# MB9AF34xN register map
File version: 1.7
Registers are 32-bit, read-write, reset 0x0 unless marked. A register's access mark holds for its fields unless they carry their own. Offsets are from the block's base; [hi:lo] are bit positions; {n}, {i} and the like mark numbered series.

## INTREQ — Interrupts
Base 0x40031000
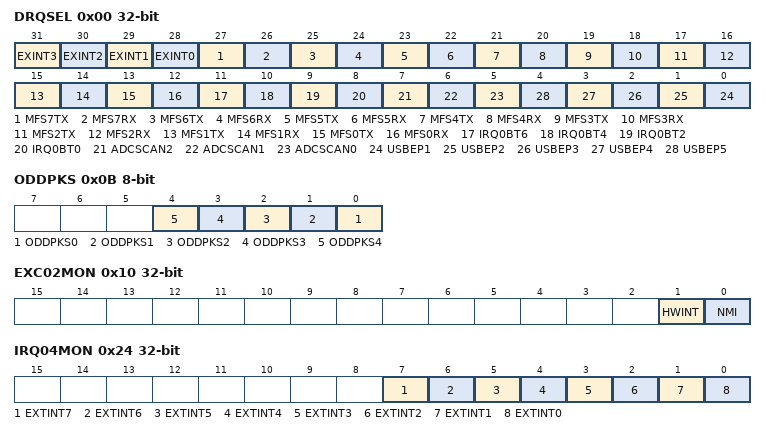
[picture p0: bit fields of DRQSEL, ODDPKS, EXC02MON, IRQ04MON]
0x00 DRQSEL — DMA Request Selection Register
  [31] EXINT3 — The interrupt signal of the external interrupt ch.3 is output as a transfer request to the DMAC (including extension).
  [30] EXINT2 — The interrupt signal of the external interrupt ch.2 is output as a transfer request to the DMAC (including extension).
  [29] EXINT1 — The interrupt signal of the external interrupt ch.1 is output as a transfer request to the DMAC (including extension).
  [28] EXINT0 — The interrupt signal of the external interrupt ch.0 is output as a transfer request to the DMAC (including extension).
  [27] MFS7TX — The transmission interrupt signal of the MFS ch.7 is output as a transfer request to the DMAC (including extension).
  [26] MFS7RX — The reception interrupt signal of the MFS ch.7 is output as a transfer request to the DMAC (including extension).
  [25] MFS6TX — The transmission interrupt signal of the MFS ch.6 is output as a transfer request to the DMAC (including extension).
  [24] MFS6RX — The reception interrupt signal of the MFS ch.6 is output as a transfer request to the DMAC (including extension).
  [23] MFS5TX — The transmission interrupt signal of the MFS ch.5 is output as a transfer request to the DMAC (including extension).
  [22] MFS5RX — The reception interrupt signal of the MFS ch.5 is output as a transfer request to the DMAC (including extension).
  [21] MFS4TX — The transmission interrupt signal of the MFS ch.4 is output as a transfer request to the DMAC (including extension).
  [20] MFS4RX — The reception interrupt signal of the MFS ch.4 is output as a transfer request to the DMAC (including extension).
  [19] MFS3TX — The transmission interrupt signal of the MFS ch.3 is output as a transfer request to the DMAC (including extension).
  [18] MFS3RX — The reception interrupt signal of the MFS ch.3 is output as a transfer request to the DMAC (including extension).
  [17] MFS2TX — The transmission interrupt signal of the MFS ch.2 is output as a transfer request to the DMAC (including extension).
  [16] MFS2RX — The reception interrupt signal of the MFS ch.2 is output as a transfer request to the DMAC (including extension).
  [15] MFS1TX — The transmission interrupt signal of the MFS ch.1 is output as a transfer request to the DMAC (including extension).
  [14] MFS1RX — The reception interrupt signal of the MFS ch.1 is output as a transfer request to the DMAC (including extension).
  [13] MFS0TX — The transmission interrupt signal of the MFS ch.0 is output as a transfer request to the DMAC (including extension).
  [12] MFS0RX — The reception interrupt signal of the MFS ch.0 is output as a transfer request to the DMAC (including extension).
  [11] IRQ0BT6 — The IRQ0 interrupt signal of the base timer ch.6 is output as a transfer request to the DMAC.
  [10] IRQ0BT4 — The IRQ0 interrupt signal of the base timer ch.4 is output as a transfer request to the DMAC.
  [9] IRQ0BT2 — The IRQ0 interrupt signal of the base timer ch.3 is output as a transfer request to the DMAC.
  [8] IRQ0BT0 — The IRQ0 interrupt signal of the base timer ch.0 is output as a transfer request to the DMAC.
  [7] ADCSCAN2 — The scan conversion interrupt signal of the A/D converter unit 2 is output as a transfer request to the DMAC.
  [6] ADCSCAN1 — The scan conversion interrupt signal of the A/D converter unit 1 is output as a transfer request to the DMAC.
  [5] ADCSCAN0 — The scan conversion interrupt signal of the A/D converter unit 0 is output as a transfer request to the DMAC.
  [n-1] USBEP{n} (n=1..5) — The EP{n} DRQ interrupt signal of the USB ch.0 is output as a transfer request to the DMAC.
0x0B ODDPKS 8-bit — USB ch.0 Odd Packet Size DMA Enable Register
  [n] ODDPKS{n} (n=0..4) — "When the transfer destination address of DMAC is USB.EP{n+1}DT, the bit width of the last transfer data is converted to Byte."
0x0C IRQCMODE — Interrupt Factor Vector Relocate Setting Register
  [0] IRQCMODE — Interrupt Factor Vector Relocate Setting
0x10 EXC02MON ro — EXC02 batch read register
  [1] HWINT — Hardware watchdog timer interrupt request
  [0] NMI — External NMIX pin interrupt request
0x14 IRQ00MON ro — IRQ00 Batch Read Register
  [0] FCSINT — Anomalous frequency detection by CSV interrupt request
0x18 IRQ01MON ro — IRQ01 Batch Read Register
  [0] SWWDTINT — Software watchdog timer interrupt request
0x1C IRQ02MON ro — IRQ02 Batch Read Register
  [0] LVDINT — Low voltage detection (LVD) interrupt request
0x24 IRQ04MON ro — IRQ04 Batch Read Register
  [7] EXTINT7 — Interrupt request on external interrupt ch.7
  [6] EXTINT6 — Interrupt request on external interrupt ch.6
  [5] EXTINT5 — Interrupt request on external interrupt ch.5
  [4] EXTINT4 — Interrupt request on external interrupt ch.4
  [3] EXTINT3 — Interrupt request on external interrupt ch.3
  [2] EXTINT2 — Interrupt request on external interrupt ch.2
  [1] EXTINT1 — Interrupt request on external interrupt ch.1
  [0] EXTINT0 — Interrupt request on external interrupt ch.0
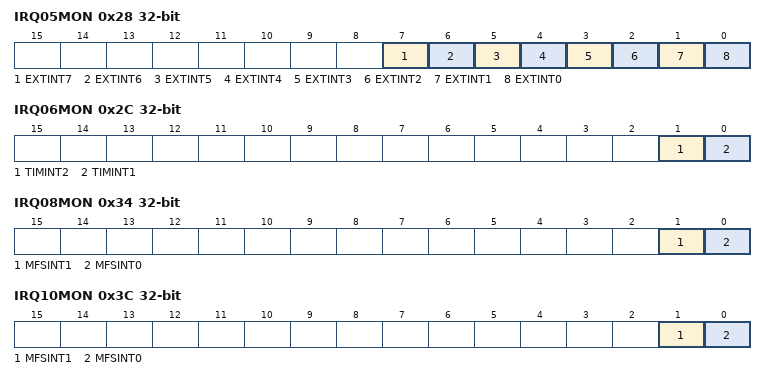
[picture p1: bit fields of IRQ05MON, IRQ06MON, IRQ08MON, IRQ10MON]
0x28 IRQ05MON ro — IRQ05 Batch Read Register
  [7] EXTINT7 — Interrupt request on external interrupt ch.15
  [6] EXTINT6 — Interrupt request on external interrupt ch.14
  [5] EXTINT5 — Interrupt request on external interrupt ch.13
  [4] EXTINT4 — Interrupt request on external interrupt ch.12
  [3] EXTINT3 — Interrupt request on external interrupt ch.11
  [2] EXTINT2 — Interrupt request on external interrupt ch.10
  [1] EXTINT1 — Interrupt request on external interrupt ch.9
  [0] EXTINT0 — Interrupt request on external interrupt ch.8
0x2C IRQ06MON ro — IRQ06 Batch Read Register
  [1] TIMINT2 — Dual timer 2 interrupt request
  [0] TIMINT1 — Dual timer 1 interrupt request
0x30 IRQ07MON ro — IRQ07 Batch Read Register
  [0] MFSINT — Reception interrupt request on MFS ch.0
0x34 IRQ08MON ro — IRQ08 Batch Read Register
  [1] MFSINT1 — Status interrupt request on MFS ch.0
  [0] MFSINT0 — Transmission interrupt request on MFS ch.0
0x38 IRQ09MON ro — IRQ09 Batch Read Register
  [0] MFSINT — Reception interrupt request on MFS ch.1
0x3C IRQ10MON ro — IRQ10 Batch Read Register
  [1] MFSINT1 — Status interrupt request on MFS ch.1
  [0] MFSINT0 — Transmission interrupt request on MFS ch.1
0x40 IRQ11MON ro — IRQ11 Batch Read Register
  [0] MFSINT — Reception interrupt request on MFS ch.2
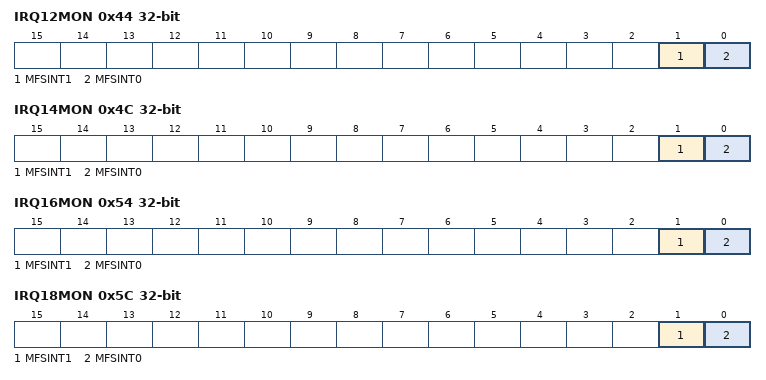
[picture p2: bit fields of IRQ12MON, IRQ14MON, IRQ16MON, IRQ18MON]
0x44 IRQ12MON ro — IRQ12 Batch Read Register
  [1] MFSINT1 — Status interrupt request on MFS ch.2
  [0] MFSINT0 — Transmission interrupt request on MFS ch.2
0x48 IRQ13MON ro — IRQ13 Batch Read Register
  [0] MFSINT — Reception interrupt request on MFS ch.3
0x4C IRQ14MON ro — IRQ14 Batch Read Register
  [1] MFSINT1 — Status interrupt request on MFS ch.3
  [0] MFSINT0 — Transmission interrupt request on MFS ch.3
0x50 IRQ15MON ro — IRQ15 Batch Read Register
  [0] MFSINT — Reception interrupt request on MFS ch.4
0x54 IRQ16MON ro — IRQ16 Batch Read Register
  [1] MFSINT1 — Status interrupt request on MFS ch.4
  [0] MFSINT0 — Transmission interrupt request on MFS ch.4
0x58 IRQ17MON ro — IRQ17 Batch Read Register
  [0] MFSINT — Reception interrupt request on MFS ch.5
0x5C IRQ18MON ro — IRQ18 Batch Read Register
  [1] MFSINT1 — Status interrupt request on MFS ch.5
  [0] MFSINT0 — Transmission interrupt request on MFS ch.5
0x60 IRQ19MON ro — IRQ19 Batch Read Register
  [0] MFSINT — Reception interrupt request on MFS ch.6
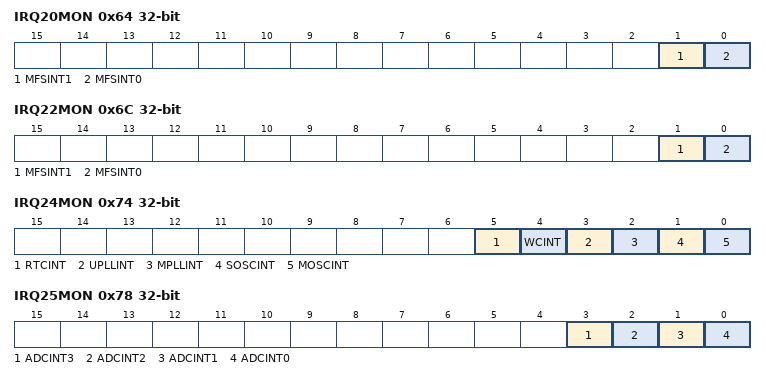
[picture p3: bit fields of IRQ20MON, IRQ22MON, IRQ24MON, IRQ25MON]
0x64 IRQ20MON ro — IRQ20 Batch Read Register
  [1] MFSINT1 — Status interrupt request on MFS ch.6
  [0] MFSINT0 — Transmission interrupt request on MFS ch.6
0x68 IRQ21MON ro — IRQ21 Batch Read Register
  [0] MFSINT — Reception interrupt request on MFS ch.7
0x6C IRQ22MON ro — IRQ22 Batch Read Register
  [1] MFSINT1 — Status interrupt request on MFS ch.7
  [0] MFSINT0 — Transmission interrupt request on MFS ch.7
0x74 IRQ24MON ro — IRQ24 Batch Read Register
  [5] RTCINT — RTC interrupt request
  [4] WCINT — Watch counter interrupt request
  [3] UPLLINT — Stabilization wait completion interrupt request for USB or USB/Ethernet PLL oscillation.
  [2] MPLLINT — Stabilization wait completion interrupt request for main PLL oscillation
  [1] SOSCINT — Stabilization wait completion interrupt request for sub-clock oscillation
  [0] MOSCINT — Stabilization wait completion interrupt request for main clock oscillation
0x78 IRQ25MON ro — IRQ25 Batch Read Register
  [3] ADCINT3 — Conversion result comparison interrupt request in the corresponding A/D unit 0.
  [2] ADCINT2 — FIFO overrun interrupt request in the corresponding A/D unit 0.
  [1] ADCINT1 — Scan conversion interrupt request in the corresponding A/D unit 0.
  [0] ADCINT0 — Priority conversion interrupt request in the corresponding A/D unit 0.
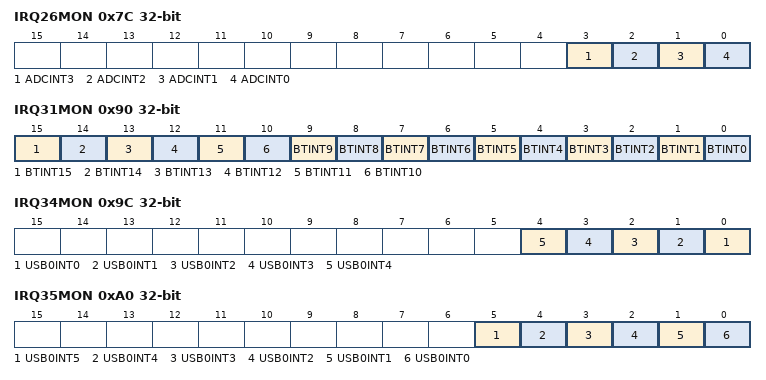
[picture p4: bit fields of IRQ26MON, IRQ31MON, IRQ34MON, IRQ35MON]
0x7C IRQ26MON ro — IRQ26 Batch Read Register
  [3] ADCINT3 — Conversion result comparison interrupt request in the corresponding A/D unit 1
  [2] ADCINT2 — FIFO overrun interrupt request in the corresponding A/D unit 1
  [1] ADCINT1 — Scan conversion interrupt request in the corresponding A/D unit 1
  [0] ADCINT0 — Priority conversion interrupt request in the corresponding A/D unit 1
0x90 IRQ31MON ro — IRQ31 Batch Read Register
  [15] BTINT15 — IRQ1 interrupt request on the base timer ch.7
  [14] BTINT14 — IRQ0 interrupt request on the base timer ch.7
  [13] BTINT13 — IRQ1 interrupt request on the base timer ch.6
  [12] BTINT12 — IRQ0 interrupt request on the base timer ch.6
  [11] BTINT11 — IRQ1 interrupt request on the base timer ch.5
  [10] BTINT10 — IRQ0 interrupt request on the base timer ch.5
  [9] BTINT9 — IRQ1 interrupt request on the base timer ch.4
  [8] BTINT8 — IRQ0 interrupt request on the base timer ch.4
  [7] BTINT7 — IRQ1 interrupt request on the base timer ch.3
  [6] BTINT6 — IRQ0 interrupt request on the base timer ch.3
  [5] BTINT5 — IRQ1 interrupt request on the base timer ch.2
  [4] BTINT4 — IRQ0 interrupt request on the base timer ch.2
  [3] BTINT3 — IRQ1 interrupt request on the base timer ch.1
  [2] BTINT2 — IRQ0 interrupt request on the base timer ch.1
  [1] BTINT1 — IRQ1 interrupt request on the base timer ch.0
  [0] BTINT0 — IRQ0 interrupt request on the base timer ch.0
0x9C IRQ34MON ro — IRQ34 Batch Read Register
  [n] USB0INT{n} (n=0..4) — Endpoint {n+1} DRQ interrupt request on the USB ch.0
0xA0 IRQ35MON ro — IRQ35 Batch Read Register
  [5] USB0INT5 — "Status (SOFIRQ, CMPIRO) interrupt request on the USB ch.0 "
  [4] USB0INT4 — "Status (DIRQ, URIRQ, RWKIRQ, CNNIRQ) interrupt request on the USB ch.0 "
  [3] USB0INT3 — Status (SPK) interrupt request on the USB ch.0
  [2] USB0INT2 — "Status (SUSP, SOF, BRST, CONF, WKUP) interrupt request on the USB ch.0 "
  [1] USB0INT1 — Endpoint 0 DRQO interrupt request on the USB ch.0
  [0] USB0INT0 — Endpoint 0 DRQI interrupt request on the USB ch.0
0xA4 IRQ36MON ro — IRQ36 Batch Read Register
  [5] RCEC0INT — Interrupt request for HDMI-CEC/Remote Control Reception ch.0
0xA8 IRQ37MON ro — IRQ37 Batch Read Register
  [6] RCEC1INT — Interrupt request for HDMI-CEC/Remote Control Reception ch.1
0xAC IRQ38MON ro — IRQ38 Batch Read Register
  [0] DMAINT — Interrupt request on DMA ch.0.
0xB0 IRQ39MON ro — IRQ39 Batch Read Register
  [0] DMAINT — Interrupt request on DMA ch.1.
0xB4 IRQ40MON ro — IRQ40 Batch Read Register
  [0] DMAINT — Interrupt request on DMA ch.2.
0xB8 IRQ41MON ro — IRQ41 Batch Read Register
  [0] DMAINT — Interrupt request on DMA ch.3.
0xBC IRQ42MON ro — IRQ42 Batch Read Register
  [0] DMAINT — Interrupt request on DMA ch.4.
0xC0 IRQ43MON ro — IRQ43 Batch Read Register
  [0] DMAINT — Interrupt request on DMA ch.5.
0xC4 IRQ44MON ro — IRQ44 Batch Read Register
  [0] DMAINT — Interrupt request on DMA ch.6.
0xC8 IRQ45MON ro — IRQ45 Batch Read Register
  [0] DMAINT — Interrupt request on DMA ch.7.
0xD0 IRQ47MON ro — IRQ47 Batch Read Register
  [11] FLASHINT — "RDY, HANG interrupt request for flash "
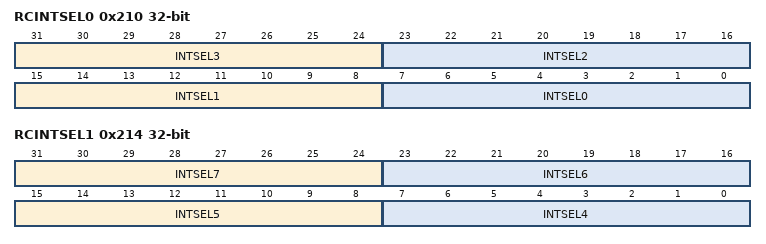
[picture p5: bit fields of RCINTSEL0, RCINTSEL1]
0x210 RCINTSEL0 — Interrupt Factor Selection Register 0
  [31:24] INTSEL3 — select the interrupt factor of the interrupt vector No.22.
  [23:16] INTSEL2 — select the interrupt factor of the interrupt vector No.21.
  [15:8] INTSEL1 — select the interrupt factor of the interrupt vector No.20.
  [7:0] INTSEL0 — select the interrupt factor of the interrupt vector No.19.
0x214 RCINTSEL1 — Interrupt Factor Selection Register 1
  [31:24] INTSEL7 — select the interrupt factor of the interrupt vector No.26.
  [23:16] INTSEL6 — select the interrupt factor of the interrupt vector No.25.
  [15:8] INTSEL5 — select the interrupt factor of the interrupt vector No.24.
  [7:0] INTSEL4 — select the interrupt factor of the interrupt vector No.23.

## Notices in the file
Licence Terms
FUJITSU SEMICONDUCTOR LIMITED (gLICENSORh) hereby grants and
you (gLICENSEEh) hereby accept a non transferable, non-exclusive
licence to use and copy the deliverables (gDeliverablesh) solely for
the purpose of; (i) developing LICENSEEfs development tools and
distributing such development tools to third parties; (ii) generating
derivative representations of the Deliverables to develop and debug
software for LICENSORfs targeted devices or device series identified
within the Deliverables, (together the gPurposeh) under the following
terms and conditions:
1. Ownership.
The Deliverables are the property of LICENSOR. LICENSEE acquires no
right, title or interest in the Deliverables other than the licence
rights granted herein.
2. Use.
LICENSEE shall only be permitted to use the Deliverables for the
Purpose. LICENSEE shall not reverse engineer, decompile or
disassemble the Deliverables, in whole or in part.
3. Copies.
All copies of the Deliverables must bear the same notice(s) contained
on the original copies of the Deliverables.
4. No Warranty.
THE DELIVERABLES ARE PROVIDED gAS ISh AND ANY EXPRESS, IMPLIED OR
STATUTORY WARRANTIES, INCLUDING, BUT NOT LIMITED TO, THE IMPLIED
WARRANTIES OF MERCHANTABILITY, SATISFACTORY QUALITY AND FITNESS FOR
A PARTICULAR PURPOSE ARE DISCLAIMED.
IN NO EVENT SHALL LICENSOR BE LIABLE FOR ANY DIRECT, INDIRECT,
INCIDENTAL, SPECIAL, EXEMPLARY, OR CONSEQUENTIAL DAMAGES HOWEVER CAUSED
AND ON ANY THEORY OF LIABILITY, WHETHER IN CONTRACT, STRICT LIABILITY,
OR TORT (INCLUDING NEGLIGENCE OR OTHERWISE) ARISING IN ANY WAY OUT OF
THE USE OF THE DELIVERABLES, EVEN IF ADVISED OF THE POSSIBILITY OF SUCH
DAMAGE.
LICENSEE EXPRESSLY ASSUMES ALL LIABILITIES AND RISKS, FOR USE OR
OPERATION OF THE DELIVERABLES.
5.In the event that LICENSEE receives early access to the Deliverables,
LICENSEE acknowledges and agrees that;
(a) notwithstanding the licence grants above, LICENSEE shall only be
permitted to use the Deliverables solely internally for evaluation and
providing feedback to LICENSOR;
(b) except with respect to the limited licence grants in 5(a), LICENSEE
shall be subject to all of the terms and conditions set out above; and
(c) the Deliverables are confidential information and LICENSEE shall
maintain in confidence the Deliverables and apply security measures no
less stringent than the measures that LICENSEE applies to its own like
information, but not less than a reasonable degree of care, to prevent
unauthorised disclosure and use of the Deliverables.
